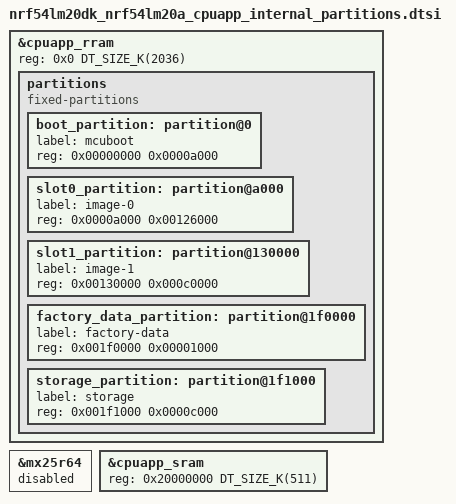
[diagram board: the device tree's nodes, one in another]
/*
 * Copyright (c) 2025 Nordic Semiconductor ASA
 *
 * SPDX-License-Identifier: LicenseRef-Nordic-5-Clause
 */

/delete-node/ &boot_partition;
/delete-node/ &slot0_partition;
/delete-node/ &slot1_partition;
/delete-node/ &storage_partition;

/* restore full RRAM and SRAM space - by default some parts are dedicated to FLRP */
&cpuapp_rram {
	reg = <0x0 DT_SIZE_K(2036)>;

	partitions {
		compatible = "fixed-partitions";
		#address-cells = <1>;
		#size-cells = <1>;

		boot_partition: partition@0 {
			label = "mcuboot";
			reg = <0x00000000 0x0000a000>;
		};

		slot0_partition: partition@a000 {
			label = "image-0";
			reg = <0x0000a000 0x00126000>;
		};

		/* Compression ratio 34.75% */
		slot1_partition: partition@130000 {
			label = "image-1";
			reg = <0x00130000 0x000c0000>;
		};

		factory_data_partition: partition@1f0000 {
			label = "factory-data";
			reg = <0x001f0000 0x00001000>;
		};

		storage_partition: partition@1f1000 {
			label = "storage";
			reg = <0x001f1000 0x0000c000>;
		};
	};
};

&mx25r64 {
	status = "disabled";
};

&cpuapp_sram {
	reg = <0x20000000 DT_SIZE_K(511)>;
	ranges = <0x0 0x20000000 DT_SIZE_K(511)>;
};
